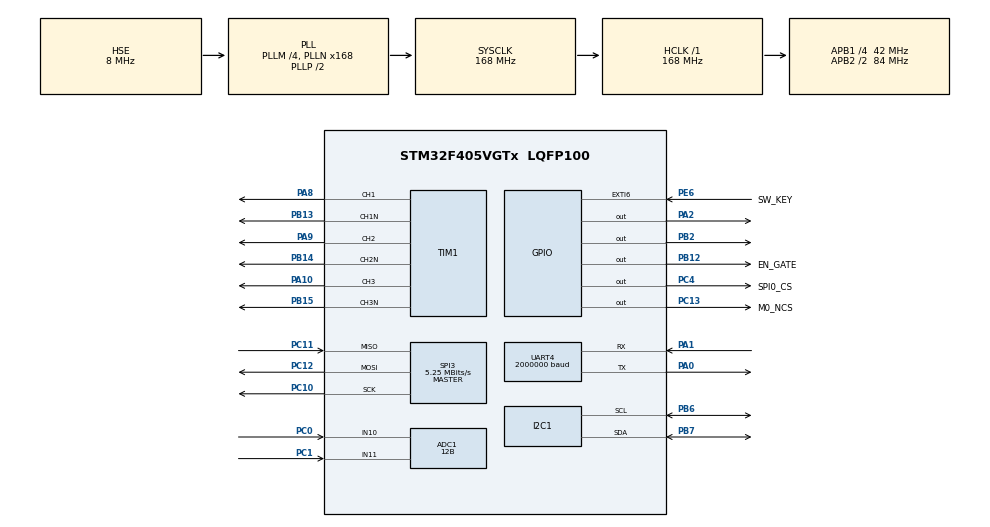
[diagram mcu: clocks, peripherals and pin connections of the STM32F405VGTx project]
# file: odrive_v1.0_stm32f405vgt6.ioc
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ADC1.Channel-0\#ChannelRegularConversion=ADC_CHANNEL_10
ADC1.Channel-2\#ChannelInjectedConversion=ADC_CHANNEL_10
ADC1.Channel-3\#ChannelInjectedConversion=ADC_CHANNEL_11
ADC1.ExternalTrigInjecConv=ADC_EXTERNALTRIGINJECCONV_T1_CC4
ADC1.ExternalTrigInjecConvEdge=ADC_EXTERNALTRIGINJECCONVEDGE_FALLING
ADC1.InjNumberOfConversion=2
ADC1.InjectedOffset-2\#ChannelInjectedConversion=0
ADC1.InjectedOffset-3\#ChannelInjectedConversion=0
ADC1.InjectedRank-2\#ChannelInjectedConversion=1
ADC1.InjectedRank-3\#ChannelInjectedConversion=2
ADC1.NbrOfConversion=1
ADC1.NbrOfConversionFlag=1
ADC1.Rank-0\#ChannelRegularConversion=1
ADC1.Resolution=ADC_RESOLUTION_12B
ADC1.SamplingTime-0\#ChannelRegularConversion=ADC_SAMPLETIME_3CYCLES
ADC1.SamplingTime-2\#ChannelInjectedConversion=ADC_SAMPLETIME_3CYCLES
ADC1.SamplingTime-3\#ChannelInjectedConversion=ADC_SAMPLETIME_3CYCLES
ADC1.master=1
Mcu.Family=STM32F4
Mcu.Name=STM32F405VGTx
Mcu.Package=LQFP100
NVIC.ADC_IRQn=true\:0\:0\:false\:false\:true\:true\:true\:true
NVIC.EXTI9_5_IRQn=true\:0\:0\:false\:false\:true\:true\:true\:true
NVIC.PriorityGroup=NVIC_PRIORITYGROUP_4
NVIC.TIM1_BRK_TIM9_IRQn=true\:0\:0\:false\:false\:true\:true\:true\:true
NVIC.TIM1_CC_IRQn=true\:0\:0\:false\:false\:true\:true\:true\:true
NVIC.TIM1_TRG_COM_TIM11_IRQn=true\:0\:0\:false\:false\:true\:true\:true\:true
NVIC.TIM1_UP_TIM10_IRQn=true\:0\:0\:false\:false\:true\:true\:true\:true
NVIC.TIM2_IRQn=true\:0\:0\:false\:false\:true\:true\:true\:true
PA0-WKUP.Mode=Asynchronous
PA0-WKUP.Signal=UART4_TX
PA1.Mode=Asynchronous
PA1.Signal=UART4_RX
PA10.Signal=S_TIM1_CH3
PA13.Mode=Serial_Wire
PA13.Signal=SYS_JTMS-SWDIO
PA14.Mode=Serial_Wire
PA14.Signal=SYS_JTCK-SWCLK
PA2.Signal=GPIO_Output
PA8.Signal=S_TIM1_CH1
PA9.Signal=S_TIM1_CH2
PB12.GPIO_Label=EN_GATE
PB12.Signal=GPIO_Output
PB13.Mode=PWM Generation1 CH1 CH1N
PB13.Signal=TIM1_CH1N
PB14.Mode=PWM Generation2 CH2 CH2N
PB14.Signal=TIM1_CH2N
PB15.Mode=PWM Generation3 CH3 CH3N
PB15.Signal=TIM1_CH3N
PB2.Signal=GPIO_Output
PB6.Mode=I2C
PB6.Signal=I2C1_SCL
PB7.Mode=I2C
PB7.Signal=I2C1_SDA
PC0.Signal=ADCx_IN10
PC1.Signal=ADCx_IN11
PC10.Mode=Full_Duplex_Master
PC10.Signal=SPI3_SCK
PC11.Mode=Full_Duplex_Master
PC11.Signal=SPI3_MISO
PC12.Mode=Full_Duplex_Master
PC12.Signal=SPI3_MOSI
PC13-ANTI_TAMP.GPIO_Label=M0_NCS
PC13-ANTI_TAMP.Signal=GPIO_Output
PC4.GPIO_Label=SPI0_CS
PC4.Signal=GPIO_Output
PE6.GPIO_Label=SW_KEY
PE6.GPIO_PuPd=GPIO_PULLDOWN
PE6.Signal=GPXTI6
PH0-OSC_IN.Mode=HSE-External-Oscillator
PH0-OSC_IN.Signal=RCC_OSC_IN
PH1-OSC_OUT.Mode=HSE-External-Oscillator
PH1-OSC_OUT.Signal=RCC_OSC_OUT
ProjectManager.HeapSize=0x200
ProjectManager.StackSize=0x1000
ProjectManager.TargetToolchain=CMake
RCC.48MHZClocksFreq_Value=84000000
RCC.AHBFreq_Value=168000000
RCC.APB1CLKDivider=RCC_HCLK_DIV4
RCC.APB1Freq_Value=42000000
RCC.APB1TimFreq_Value=84000000
RCC.APB2CLKDivider=RCC_HCLK_DIV2
RCC.APB2Freq_Value=84000000
RCC.APB2TimFreq_Value=168000000
RCC.CortexFreq_Value=168000000
RCC.HCLKFreq_Value=168000000
RCC.HSE_VALUE=8000000
RCC.HSI_VALUE=16000000
RCC.LSE_VALUE=32768
RCC.PLLM=4
RCC.PLLN=168
RCC.PLLSourceVirtual=RCC_PLLSOURCE_HSE
RCC.SYSCLKFreq_VALUE=168000000
RCC.SYSCLKSource=RCC_SYSCLKSOURCE_PLLCLK
RCC.VCOOutputFreq_Value=336000000
SH.ADCx_IN10.0=ADC1_IN10,IN10
SH.ADCx_IN11.0=ADC1_IN11,IN11
SH.S_TIM1_CH1.0=TIM1_CH1,PWM Generation1 CH1 CH1N
SH.S_TIM1_CH2.0=TIM1_CH2,PWM Generation2 CH2 CH2N
SH.S_TIM1_CH3.0=TIM1_CH3,PWM Generation3 CH3 CH3N
SPI3.BaudRatePrescaler=SPI_BAUDRATEPRESCALER_8
SPI3.CLKPhase=SPI_PHASE_2EDGE
SPI3.CLKPolarity=SPI_POLARITY_HIGH
SPI3.CalculateBaudRate=5.25 MBits/s
SPI3.DataSize=SPI_DATASIZE_8BIT
SPI3.Direction=SPI_DIRECTION_2LINES
SPI3.Mode=SPI_MODE_MASTER
SPI3.VirtualType=VM_MASTER
STMicroelectronics.X-CUBE-ALGOBUILD.1.4.0.LibraryCcDSPOoLibraryJjDSPOoLibrary=true
TIM1.AutoReloadPreload=TIM_AUTORELOAD_PRELOAD_ENABLE
TIM1.Channel-PWM\ Generation1\ CH1\ CH1N=TIM_CHANNEL_1
TIM1.Channel-PWM\ Generation2\ CH2\ CH2N=TIM_CHANNEL_2
TIM1.Channel-PWM\ Generation3\ CH3\ CH3N=TIM_CHANNEL_3
TIM1.Channel-PWM\ Generation4\ No\ Output=TIM_CHANNEL_4
TIM1.CounterMode=TIM_COUNTERMODE_CENTERALIGNED1
TIM1.DeadTime=100
TIM1.OCMode_PWM-PWM\ Generation1\ CH1\ CH1N=TIM_OCMODE_PWM2
TIM1.OCMode_PWM-PWM\ Generation2\ CH2\ CH2N=TIM_OCMODE_PWM2
TIM1.OCMode_PWM-PWM\ Generation3\ CH3\ CH3N=TIM_OCMODE_PWM2
TIM1.TIM_MasterOutputTrigger=TIM_TRGO_OC4REF
TIM2.AutoReloadPreload=TIM_AUTORELOAD_PRELOAD_ENABLE
UART4.BaudRate=2000000
UART4.VirtualMode=Asynchronous
VP_STMicroelectronics.X-CUBE-ALGOBUILD_VS_DSPOoLibraryJjLibrary_1.4.0_1.4.0.Mode=DSPOoLibraryJjLibrary
VP_TIM1_VS_ClockSourceINT.Mode=Internal
VP_TIM1_VS_no_output4.Mode=PWM Generation4 No Output
VP_TIM2_VS_ClockSourceINT.Mode=Internal
board=custom

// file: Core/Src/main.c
/* USER CODE BEGIN Header */
/**
  ******************************************************************************
  * @file           : main.c
  * @brief          : Main program body
  ******************************************************************************
  * @attention
  *
  * Copyright (c) 2026 STMicroelectronics.
  * All rights reserved.
  *
  * This software is licensed under terms that can be found in the LICENSE file
  * in the root directory of this software component.
  * If no LICENSE file comes with this software, it is provided AS-IS.
  *
  ******************************************************************************
  */
/* USER CODE END Header */
#include "main.h"
#include "adc.h"
#include "i2c.h"
#include "spi.h"
#include "tim.h"
#include "usart.h"
#include "gpio.h"

/* USER CODE BEGIN Includes */
extern int mymain(void);

/* USER CODE END Includes */

void SystemClock_Config(void);

int main(void)
{

  /* MCU Configuration--------------------------------------------------------*/

  /* Reset of all peripherals, Initializes the Flash interface and the Systick. */
  HAL_Init();

  /* Configure the system clock */
  SystemClock_Config();

  /* Initialize all configured peripherals */
  MX_GPIO_Init();
  MX_UART4_Init();
  MX_SPI3_Init();
  MX_TIM1_Init();
  MX_I2C1_Init();
  MX_ADC1_Init();
  MX_TIM2_Init();
  /* USER CODE BEGIN 2 */
  mymain();

  /* USER CODE END 2 */

  /* Infinite loop */
  while (1)
  {

  }
}

void SystemClock_Config(void)
{
  RCC_OscInitTypeDef RCC_OscInitStruct = {0};
  RCC_ClkInitTypeDef RCC_ClkInitStruct = {0};

  /** Configure the main internal regulator output voltage
  */
  __HAL_RCC_PWR_CLK_ENABLE();
  __HAL_PWR_VOLTAGESCALING_CONFIG(PWR_REGULATOR_VOLTAGE_SCALE1);

  /** Initializes the RCC Oscillators according to the specified parameters
  * in the RCC_OscInitTypeDef structure.
  */
  RCC_OscInitStruct.OscillatorType = RCC_OSCILLATORTYPE_HSE;
  RCC_OscInitStruct.HSEState = RCC_HSE_ON;
  RCC_OscInitStruct.PLL.PLLState = RCC_PLL_ON;
  RCC_OscInitStruct.PLL.PLLSource = RCC_PLLSOURCE_HSE;
  RCC_OscInitStruct.PLL.PLLM = 4;
  RCC_OscInitStruct.PLL.PLLN = 168;
  RCC_OscInitStruct.PLL.PLLP = RCC_PLLP_DIV2;
  RCC_OscInitStruct.PLL.PLLQ = 4;
  if (HAL_RCC_OscConfig(&RCC_OscInitStruct) != HAL_OK)
  {
    Error_Handler();
  }

  /** Initializes the CPU, AHB and APB buses clocks
  */
  RCC_ClkInitStruct.ClockType = RCC_CLOCKTYPE_HCLK|RCC_CLOCKTYPE_SYSCLK
                              |RCC_CLOCKTYPE_PCLK1|RCC_CLOCKTYPE_PCLK2;
  RCC_ClkInitStruct.SYSCLKSource = RCC_SYSCLKSOURCE_PLLCLK;
  RCC_ClkInitStruct.AHBCLKDivider = RCC_SYSCLK_DIV1;
  RCC_ClkInitStruct.APB1CLKDivider = RCC_HCLK_DIV4;
  RCC_ClkInitStruct.APB2CLKDivider = RCC_HCLK_DIV2;

  if (HAL_RCC_ClockConfig(&RCC_ClkInitStruct, FLASH_LATENCY_5) != HAL_OK)
  {
    Error_Handler();
  }
}

void Error_Handler(void)
{
  __disable_irq();
  while (1)
  {
  }
}
